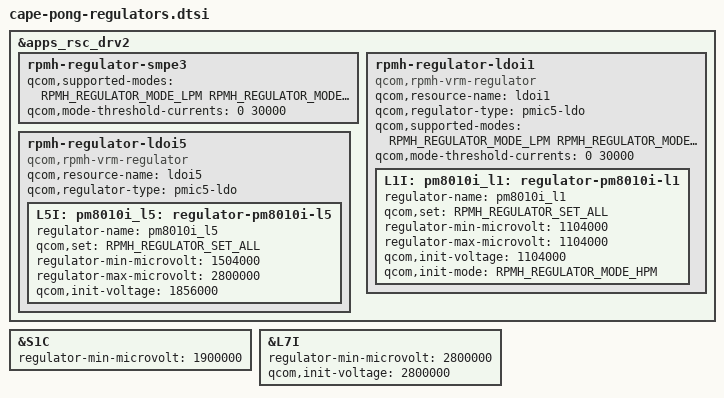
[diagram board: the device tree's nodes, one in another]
// SPDX-License-Identifier: BSD-3-Clause
// SPDX-FileCopyrightText: 2026 The PenguinOS Project

#include <dt-bindings/regulator/qcom,rpmh-regulator-levels.h>

&apps_rsc_drv2 {
	rpmh-regulator-smpe3 {
		qcom,supported-modes =
			<RPMH_REGULATOR_MODE_LPM
			RPMH_REGULATOR_MODE_HPM>;
		qcom,mode-threshold-currents = <0 30000>;
	};

	rpmh-regulator-ldoi1 {
		compatible = "qcom,rpmh-vrm-regulator";
		qcom,resource-name = "ldoi1";
		qcom,regulator-type = "pmic5-ldo";
		qcom,supported-modes =
			<RPMH_REGULATOR_MODE_LPM
			RPMH_REGULATOR_MODE_HPM>;
		qcom,mode-threshold-currents = <0 30000>;
		L1I: pm8010i_l1: regulator-pm8010i-l1 {
			regulator-name = "pm8010i_l1";
			qcom,set = <RPMH_REGULATOR_SET_ALL>;
			regulator-min-microvolt = <1104000>;
			regulator-max-microvolt = <1104000>;
			qcom,init-voltage = <1104000>;
			qcom,init-mode = <RPMH_REGULATOR_MODE_HPM>;
		};
	};

	rpmh-regulator-ldoi5 {
		compatible = "qcom,rpmh-vrm-regulator";
		qcom,resource-name = "ldoi5";
		qcom,regulator-type = "pmic5-ldo";
		L5I: pm8010i_l5: regulator-pm8010i-l5 {
			regulator-name = "pm8010i_l5";
			qcom,set = <RPMH_REGULATOR_SET_ALL>;
			regulator-min-microvolt = <1504000>;
			regulator-max-microvolt = <2800000>;
			qcom,init-voltage = <1856000>;
		};
	};
};

&S1C {
	regulator-min-microvolt = <1900000>;
};

&L7I {
	regulator-min-microvolt = <2800000>;
	qcom,init-voltage = <2800000>;
};
